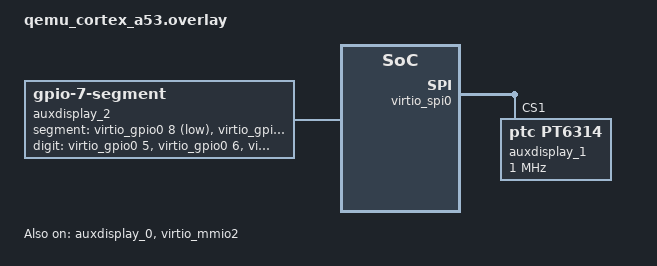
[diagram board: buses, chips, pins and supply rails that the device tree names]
/*
 * Copyright (c) 2026
 * SPDX-License-Identifier: Apache-2.0
 *
 * Turn on every auxdisplay the browser models. Requires -S virtio-i2c (for
 * &auxdisplay_0 / jhd1313@3e), -S virtio-spi (for &virtio_spi0 + NOR on CS0),
 * and -S virtio-gpio (for the gpio-7-segment digit commons / segment bus).
 *
 * PT6314 sits on CS1 so it coexists with the shell's flash/LittleFS.
 * The 7-segment module uses virtio_gpio0 pins 5–7 (digits) and 8–15
 * (A–G, DP), leaving 0–3 / 4 free for the virtio-gpio snippet's keys/LED.
 * ngpios is widened to 16 to match QEMU's virtio-gpio config space.
 *
 * Refresh runs from the vendored workqueue driver (AUXDISPLAY_GPIO_7SEG_WQ);
 * do not use in-tree AUXDISPLAY_GPIO_7SEG with virtio,gpio.
 */

#include <zephyr/dt-bindings/gpio/gpio.h>

&auxdisplay_0 {
	status = "okay";
};

&virtio_spi0 {
	auxdisplay_1: pt6314@1 {
		compatible = "ptc,pt6314";
		reg = <1>;
		spi-max-frequency = <1000000>;
		columns = <20>;
		rows = <2>;
		status = "okay";
	};
};

/* Widen the controller; virtio-gpio snippet (or this overlay) turns it okay. */
&virtio_mmio2 {
	status = "okay";
};

&virtio_gpio0 {
	status = "okay";
	ngpios = <16>;
};

/ {
	/*
	 * No `label` property on purpose. Zephyr names a device after its DT
	 * label when it has one, so `label = "7-segment LED"` is what the shell
	 * would quote — `auxdisplay write "7-segment LED" 42.` next to a plain
	 * `jhd1313@3e` and `pt6314@1`. Without it the device is `digi-display`,
	 * the node name, and the dock still reads "7-segment LED": the panel
	 * falls back to that string when the property is absent (src/dts/
	 * insights.ts).
	 */
	auxdisplay_2: digi-display {
		compatible = "gpio-7-segment";
		status = "okay";
		columns = <3>;
		rows = <1>;
		/* Common-anode style: digits active-high, segments active-low. */
		segment-gpios = <&virtio_gpio0 8 GPIO_ACTIVE_LOW>,  /* A */
				<&virtio_gpio0 9 GPIO_ACTIVE_LOW>,  /* B */
				<&virtio_gpio0 10 GPIO_ACTIVE_LOW>, /* C */
				<&virtio_gpio0 11 GPIO_ACTIVE_LOW>, /* D */
				<&virtio_gpio0 12 GPIO_ACTIVE_LOW>, /* E */
				<&virtio_gpio0 13 GPIO_ACTIVE_LOW>, /* F */
				<&virtio_gpio0 14 GPIO_ACTIVE_LOW>, /* G */
				<&virtio_gpio0 15 GPIO_ACTIVE_LOW>; /* DP */
		digit-gpios = <&virtio_gpio0 5 GPIO_ACTIVE_HIGH>,  /* DIG1 */
			      <&virtio_gpio0 6 GPIO_ACTIVE_HIGH>,  /* DIG2 */
			      <&virtio_gpio0 7 GPIO_ACTIVE_HIGH>;  /* DIG3 */
		/* ~100 Hz digit scan; workqueue + virtio round-trips need headroom. */
		refresh-period-ms = <5>;
	};
};
